# FM33A0XXX register map
File version: 1.0
CPU: SC000 r1p0, little endian, MPU, no FPU, 3 interrupt priority bits
Registers are 32-bit, read-write, reset 0x0 unless marked. A register's access mark holds for its fields unless they carry their own. Offsets are from the block's base; [hi:lo] are bit positions; {n}, {i} and the like mark numbered series.

## ANAC — ANAC Registers
Base 0x40012800
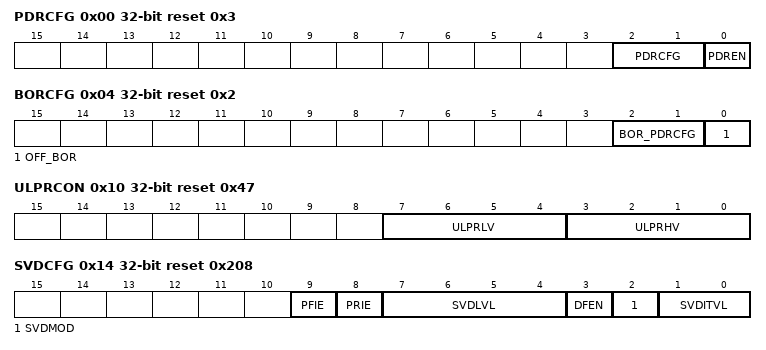
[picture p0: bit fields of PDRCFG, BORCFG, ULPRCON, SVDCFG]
0x00 PDRCFG reset 0x3 — PDR CONFIG REGISTER
  [2:1] PDRCFG — PDR CONFIG
    0=1.5V; 1=1.25V; 2=1.35V; 3=1.4V
  [0] PDREN — PDR ENABLE
0x04 BORCFG reset 0x2 — BOR CONFIG
  [2:1] BOR_PDRCFG — BOR_PDR CONFIG
    0=1.7V; 1=1.6V; 2=1.65V; 3=1.75V
  [0] OFF_BOR
0x08 LDO15CON reset 0x7 — LDO15 CONTROL REGISTER
  [3:0] TRIM_LDO15 — LDO15 TRIM DATA
0x0C VREFTRIM reset 0x1A
  [5:0] VREFTRIM — VREF TRIM DATA
0x10 ULPRCON reset 0x47 — ULP CONFIG REGISTER
  [7:4] ULPRLV — ULPLDO LOW VOLTAGE OUTPUT
  [3:0] ULPRHV — ULPLDO HIGH VOLTAGE OUTPUT
0x14 SVDCFG reset 0x208 — SVD CONFIG REGISTER
  [9] PFIE — Power Fail Interrupt Enable
  [8] PRIE — Power Restore Interrupt Enable
  [7:4] SVDLVL — SVD ALARM LEVEL
  [3] DFEN — SVD DIGITAL FILTER ENABLE
  [2] SVDMOD — SVD MODE
    0=IMTEN (INTERMITTENT ENABLE); 1=OFTEN (OFTEN ENABLE)
  [1:0] SVDITVL — SVD Interval
    0=15.625ms; 1=62.5ms; 2=256ms; 3=1s
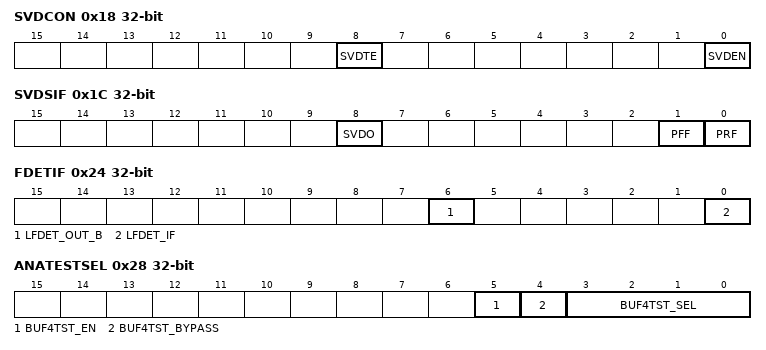
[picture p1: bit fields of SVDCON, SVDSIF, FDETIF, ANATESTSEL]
0x18 SVDCON — SVD CONTROL REGISTER
  [8] SVDTE — SVD TEST EENABLE
  [0] SVDEN — SVD ENABLE
0x1C SVDSIF — SVD STATUS AND IF
  [8] SVDO — SVD OUTPUT
  [1] PFF
  [0] PRF
0x20 FDETIE — XTLF FREQ DETECT IE
  [0] LFDET_IE
0x24 FDETIF — XTLF FREQ DETECT IF
  [6] LFDET_OUT_B, [0] LFDET_IF
0x28 ANATESTSEL — ANA TEST SELECT REGISTER
  [5] BUF4TST_EN — BUF4TST ENABLE
  [4] BUF4TST_BYPASS
  [3:0] BUF4TST_SEL — BUF FOR TEST SELECT
    0=vbe1_adc; 1=vbe2_adc; 2=vbe3_adc; 3=vcmbuf_adc; 4=vddx; 5=lfdet_out_b; 6=VDD50; 7=VREF08; {v}=AN{v-7} (v=8..15)
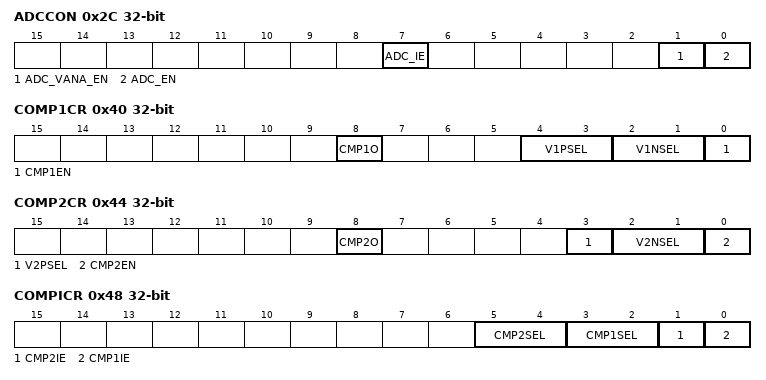
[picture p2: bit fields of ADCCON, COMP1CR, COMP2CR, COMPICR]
0x2C ADCCON — ADC CONTROL REGISTER
  [7] ADC_IE
  [1] ADC_VANA_EN — ADC OUTER VOLTAGE TEST ENABLE
  [0] ADC_EN — ADC ENABLE
0x30 ADCTRIM
  [10:0] ADC_TRIM
0x34 ADCDATA ro
  [10:0] ADC_DATA rw
0x38 ADCIF
  [0] ADC_IF — ADC IF,write 1 to clear
0x3C TRNGCON — TRNG CONTROL REGISTER
  [0] RNGEN
0x40 COMP1CR — COMP1 CONTROL REGISTER
  [8] CMP1O ro — CMP1 OUTPUT
  [4:3] V1PSEL
    0=PF6; 1=PF2; 2=PG2; 3=PG3
  [2:1] V1NSEL
    0=PF5; 1=PF1; 2=Vref 0.8V; 3=Vref/2 0.4V
  [0] CMP1EN
0x44 COMP2CR — COMP2 CONTROL REGISTER
  [8] CMP2O — CMP2 OUTPUT
  [3] V2PSEL
    0=PC15; 1=PE4
  [2:1] V2NSEL
    0=PC14; 1=PE3; 2=Vref 0.8V; 3=Vref/2 0.4V
  [0] CMP2EN — CMP2 ENABLE
0x48 COMPICR — COMP INT CONFIG REGISTER
  [5:4] CMP2SEL — CMP2 INT SOURCE SELECT
  [3:2] CMP1SEL — CMP1 INT SOURCE SELECT
  [1] CMP2IE
  [0] CMP1IE
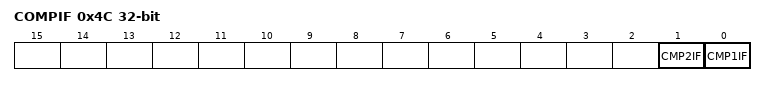
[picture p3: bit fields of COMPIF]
0x4C COMPIF
  [1] CMP2IF — CMP2IF,WRITE 1 TO CLEAR
  [0] CMP1IF — CMP1IF, WRITE 1 TO CLEAR

## RAMBIST — RAMBIST REGISTERS
Base 0x40012C00
0x00 RAMBISTCON reset 0x3 — RAMBIST CONTROL REGISTER
  [0] RAMBEN — RAMBIST ENABLE
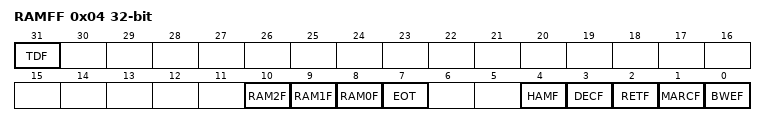
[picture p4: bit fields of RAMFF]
0x04 RAMFF — RAMBIST Fault Flag REGISTER
  [31] TDF — Total detected fault
  [10] RAM2F — RAM2 Fail
  [9] RAM1F — RAM1 Fail
  [8] RAM0F — RAM0 Fail
  [7] EOT — End of Test
  [4] HAMF — Hammer Fault
  [3] DECF — Decoder Fault
  [2] RETF — SRAM Retention Fault
  [1] MARCF — SRAM March Fault
  [0] BWEF — Byte Write Enable Fault

## BTIMER1 — BASIC TIMER1 Registers
Base 0x40013000
Same registers: BTIMER2 0x40013044
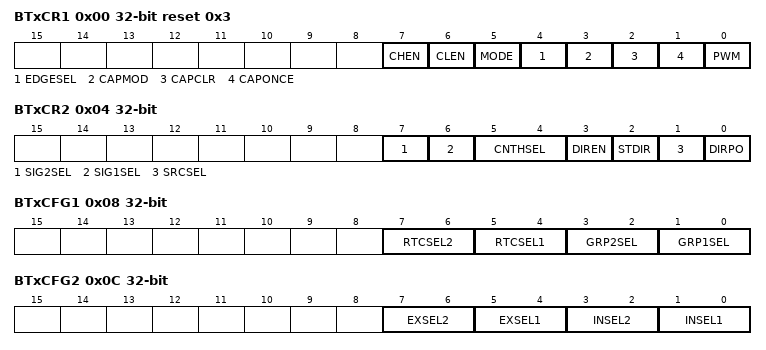
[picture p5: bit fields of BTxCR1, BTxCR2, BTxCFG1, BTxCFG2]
0x00 BTxCR1 reset 0x3 — BTIMER CONTROL REGISTER1
  [7] CHEN
  [6] CLEN
  [5] MODE
    0=8BIT_CNT; 1=16BIT_CAP
  [4] EDGESEL — EDGE SELECT
    0=POS; 1=NEG
  [3] CAPMOD — CAPTURE MODE
    0=PERIOD (PULSE PERIOD); 1=WIDTH (PULSE WIDTH)
  [2] CAPCLR — CLEAR COUNTER AT CAPTURE
    0=NOCLR; 1=CLR
  [1] CAPONCE — CAPTURE ONCE
    0=CONTINUOUS; 1=ONCE
  [0] PWM — PWM MODE OUTPUT ENABLE
0x04 BTxCR2 — BTIMER CONTROL REGISTER 2
  [7] SIG2SEL
    0=CNT_GROUP1; 1=CNT_GROUP2
  [6] SIG1SEL
    0=CAP_GROUP2; 1=CAP_GROUP1
  [5:4] CNTHSEL
    0=ETL; 1=INNERCAP; 2=INNERCNT; 3=ETL
  [3] DIREN
  [2] STDIR
  [1] SRCSEL — SOURCE SELECT
  [0] DIRPO
0x08 BTxCFG1 — BTIMER CONFIG REGISTER 1
  [7:6] RTCSEL2
    0=32768Hz; 1=RTCSec; 2=RTCMin; 3=LPTIM_OUT
  [5:4] RTCSEL1
    0=32768Hz; 1=RTCSec; 2=RTCMin; 3=LPTIM_OUT
  [3:2] GRP2SEL
    0=APBCLK; 1=RTCOUT2; 2=IN_SIG2; 3=EX_SIG2
  [1:0] GRP1SEL
    0=APBCLK; 1=RTCOUT1; 2=IN_SIG1; 3=EX_SIG1
0x0C BTxCFG2 — BTIMER CONFIG REGISTER 2
  [7:6] EXSEL2
    {v}=BT1_IN{v} (v=0..3)
  [5:4] EXSEL1
    {v}=BT1_IN{v} (v=0..3)
  [3:2] INSEL2
    0=UART_RX3; 1=UART_RX4; 2=UART_RX5; 3=RCLP/BT1_OUT
  [1:0] INSEL1
    0=UART_RX0; 1=UART_RX1; 2=UART_RX2; 3=RCLP
0x10 BT1PRES — BTIMER PRESCALE REGISTER
  [7:0] PRESCALE
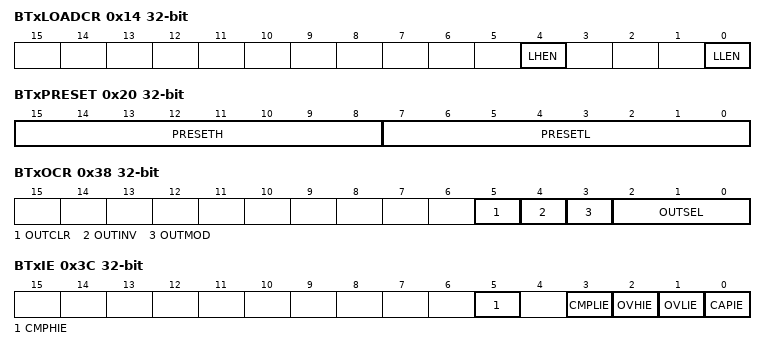
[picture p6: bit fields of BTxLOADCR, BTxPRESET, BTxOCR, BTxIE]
0x14 BTxLOADCR — BTIMER LOADER CONTROL REGISTER
  [4] LHEN — HIGH BYTE LOAD ENABLE
  [0] LLEN — LOW BYTE LOAD ENABLE
0x18 BT1xCNTL — BTIMER LOW BYTE COUNTER REGISTER
  [7:0] CNTL
0x1C BTxCNTH — BTIMER HIGH BYTE COUNTER REGISTER
  [7:0] CNTH
0x20 BTxPRESET — BTIMER PRESET REGISTER
  [15:8] PRESETH — PRESETH HIGH BYTE
  [7:0] PRESETL — PRESET LOW BYTE
0x24 BTxLOADL — BTIMER LOW BYTE LOAD REGISTER
  [7:0] LOADL
0x28 BTxLOADH — BTIMER HIGH BYTE LOAD REGISTER
  [7:0] LOADH
0x2C BTxCMPL — BTIME CMPL REGISTER
  [7:0] CMPL
0x30 BTxCMPH — BTIMER CMPH REGISTER
  [7:0] CMPH
0x34 BTxOUTCNT — BTIMER OUTCNT REGISTER
  [11:0] OUTCNT
0x38 BTxOCR — BTIMER OUTPUT CONTROL REGISTER
  [5] OUTCLR
  [4] OUTINV
  [3] OUTMOD
    0=PULSE; 1=REV
  [2:0] OUTSEL
    0=CMPH; 1=CMPL; 2=Group1; 3=Group2; 4=PWM
0x3C BTxIE — BTIMER IE REGISTER
  [5] CMPHIE, [3] CMPLIE, [2] OVHIE, [1] OVLIE, [0] CAPIE
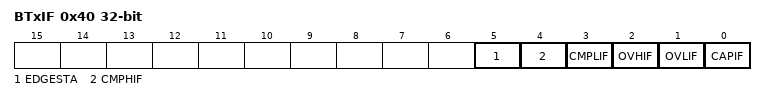
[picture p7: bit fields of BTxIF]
0x40 BTxIF — BTIMER IF REGISTER
  [5] EDGESTA, [4] CMPHIF, [3] CMPLIF, [2] OVHIF, [1] OVLIF, [0] CAPIF

## ETIMER1 — EXTENDED TIMER Registers
Base 0x40013090
Same registers: ETIMER2 0x400130B0, ETIMER3 0x400130D0, ETIMER4 0x400130F0
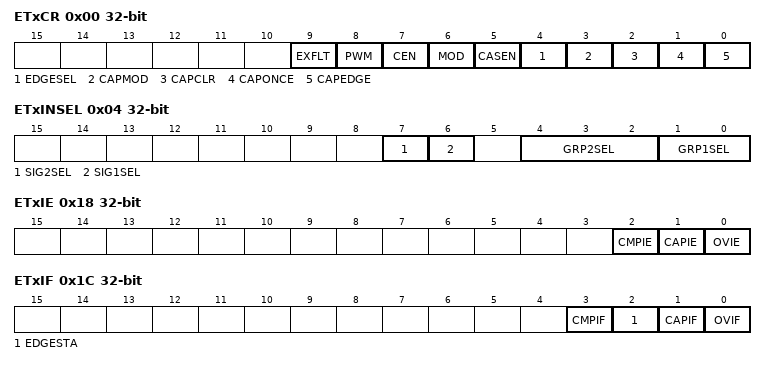
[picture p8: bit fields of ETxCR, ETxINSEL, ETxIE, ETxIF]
0x00 ETxCR — ETIMER CONTROL REGISTER
  [9] EXFLT
  [8] PWM
  [7] CEN
  [6] MOD — MODE
    0=CNT; 1=CAP
  [5] CASEN — Cascade Enable
  [4] EDGESEL — EDGE SELECT
    0=POS; 1=NEG
  [3] CAPMOD — CAPTURE MODE
    0=PERIOD (PULSE PERIOD); 1=WIDTH (PULSE WIDTH)
  [2] CAPCLR — CLEAR COUNTER AT CAPTURE
    0=NOCLR; 1=CLR
  [1] CAPONCE — CAPTURE ONCE
    0=CONTINUOUS; 1=ONCE
  [0] CAPEDGE — CAPTURE EDGE
    0=POS; 1=NEG
0x04 ETxINSEL — ETIMER INPUT SOURCE SELECT REGISTER
  [7] SIG2SEL
    0=Group2; 1=Group1
  [6] SIG1SEL
    0=Group1; 1=Group2
  [4:2] GRP2SEL
    0=UART0_RX/UART2_RX/ET3_IN1/ET4_IN1; 1=UART1_RX/UART3_RX/XTLF/XTLF; 2=XTLF/XTLF/UART4_RX/UART_RX2; 3=ET1_IN1/ET2_IN1/UART5_RX/UART_RX0; 4=ET1_IN2/ET2_IN2/RTCSEC/U7816RX0; 5=U7816RX0/U7816RX0/RFU/U7816RX1; 6=U7816RX1/U7816RX1/RFU/RTCSEC; 7=LPTO/LPTO/RFU/LPTO
  [1:0] GRP1SEL
    0=APBCLK; 1=XTLF/XTLF/ET3_IN0/ET4_IN0; 2=RCLP/RCLP/RTCSEC/RTC64HZ; 3=ET1_IN0/ET4_IN0/RCLP/LPTO
0x08 ETxPESCALE1 — ETIMER PESCALE REGISTER 1
  [7:0] PRESCALE1 — PRESCALE for Signal1
0x0C ETxPESCALE2 — ETIMER PESCALE REGISTER 2
  [7:0] PRESCALE2 — PRESCALE FOR Signal2
0x10 ETxIVR — ETIMER INIT VALUE REGISTER
  [15:0] INITVALUE
0x14 ETxCMP — ETIMER CMP REGISTER
  [15:0] CMP
0x18 ETxIE — ETIMER IE REGISTER
  [2] CMPIE, [1] CAPIE, [0] OVIE
0x1C ETxIF — ETIMER IF REGISTER
  [3] CMPIF, [2] EDGESTA, [1] CAPIF, [0] OVIF

## LPTIM — LPTIM Registers
Base 0x40013400
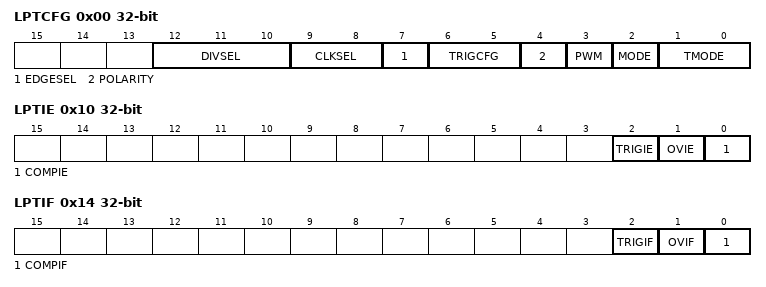
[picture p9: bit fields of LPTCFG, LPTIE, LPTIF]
0x00 LPTCFG — LPTIMER CONFIG REGISTER
  [12:10] DIVSEL — CLK DIVIDED SELECT
    0=DIV1; 1=DIV2; 2=DIV4; 3=DIV8; 4=DIV16; 5=DIV32; 6=DIV64; 7=DIV128
  [9:8] CLKSEL — CLK SOURCE SELECT
    0=LSCLK; 1=RCLP; 2=PCLK; 3=LPTIN
  [7] EDGESEL — EDGE SELECT
    0=POS; 1=NEG
  [6:5] TRIGCFG
    0=POS; 1=NEG; 2=BOTH
  [4] POLARITY
    0=POS; 1=NEG
  [3] PWM
    0=SQR; 1=PMW
  [2] MODE
    0=CONTINUOUS; 1=ONCE
  [1:0] TMODE
    0=OUT_CNT; 1=TRIG_CNT; 2=OUTER_SOURCE; 3=Timeout
0x04 LPTCNT — LPTIMER COUNTER REGISTER
  [15:0] LPTCNT
0x08 LPTCMP — LPTIMER COMPARE REGISTER
  [15:0] LPTCMP
0x0C LPTTARGET — LPTIMER TARGET REGISTER
  [15:0] LPTTARGET
0x10 LPTIE — LPTIMER IE REGISTER
  [2] TRIGIE, [1] OVIE, [0] COMPIE
0x14 LPTIF — LPTIMER IF REGISTER
  [2] TRIGIF, [1] OVIF, [0] COMPIF
0x18 LPTCTRL — LPTIMER CTRL REGISTER
  [0] LPTEN

## AES — AES Registers
Base 0x40013800
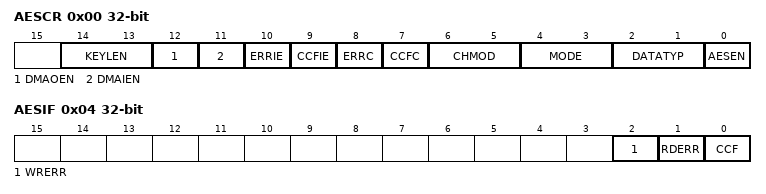
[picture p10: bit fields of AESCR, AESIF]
0x00 AESCR — AES CONTROL REGISTER
  [14:13] KEYLEN
    0=128bit; 1=192bit; 2=256bit; 3=REV
  [12] DMAOEN
  [11] DMAIEN
  [10] ERRIE
  [9] CCFIE
  [8] ERRC wo — ERR Clear
  [7] CCFC wo — CCF Clear
  [6:5] CHMOD
    0=ECB; 1=CBC; 2=CTR; 3=MultH
  [4:3] MODE
    0=ENCRYPT; 1=KEY_EXPANSION; 2=DECRYPT; 3=KEYEXP_DEC (KEY_EXPANSION + DECRYPT)
  [2:1] DATATYP
    0=32bit; 1=16bit; 2=8bit; 3=1bit
  [0] AESEN
0x04 AESIF
  [2] WRERR, [1] RDERR, [0] CCF
0x08 AESDIN — AES DATA INPUT REGISTER
0x0C AESDOUT — AES DATA OUTPUT REGISTER
{0x10+4i} AESKEY{i} (i=0..7)
  [31:0] AESKEY
{0x30+4i} AESIVR{i} (i=0..3) — AES INITIAL VECTOR{i} REGISTER
  [31:0] AESIVR

## TRNG — TRNG Registers
Base 0x40013C04
0x00 RNGOUT — TRNG OUTPUT REGISTER
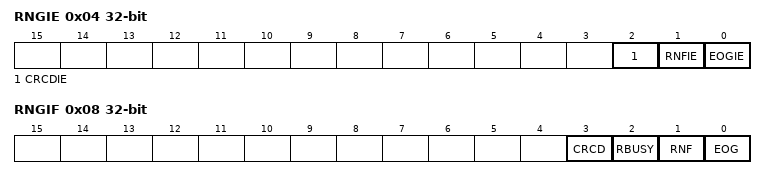
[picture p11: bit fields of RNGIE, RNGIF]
0x04 RNGIE — TRNG IE REGISTER
  [2] CRCDIE, [1] RNFIE, [0] EOGIE
0x08 RNGIF — TRNG IF REGISTER
  [3] CRCD, [2] RBUSY, [1] RNF, [0] EOG
0x0C CRCIN — CRC INPUT REGISTER
0x10 CRCCON — CRC CONTROL REGISTER
  [0] CRCEN
